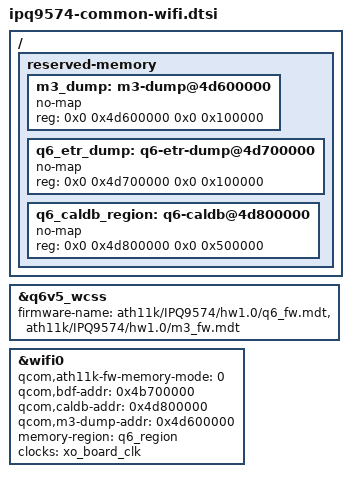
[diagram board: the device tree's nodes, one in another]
// SPDX-License-Identifier: (GPL-2.0+ OR BSD-3-Clause)

/* IPQ9574 AHB radio firmware and dump/calibration memory layout. */
/ {
	reserved-memory {
		m3_dump: m3-dump@4d600000 {
			no-map;
			reg = <0x0 0x4d600000 0x0 0x100000>;
		};

		q6_etr_dump: q6-etr-dump@4d700000 {
			no-map;
			reg = <0x0 0x4d700000 0x0 0x100000>;
		};

		q6_caldb_region: q6-caldb@4d800000 {
			no-map;
			reg = <0x0 0x4d800000 0x0 0x500000>;
		};
	};
};

&q6v5_wcss {
	firmware-name = "ath11k/IPQ9574/hw1.0/q6_fw.mdt",
			"ath11k/IPQ9574/hw1.0/m3_fw.mdt";
};

&wifi0 {
	qcom,ath11k-fw-memory-mode = <0>;
	qcom,bdf-addr = <0x4b700000>;
	qcom,caldb-addr = <0x4d800000>;
	qcom,m3-dump-addr = <0x4d600000>;
	memory-region = <&q6_region>;
	clocks = <&xo_board_clk>;
	clock-names = "xo";
	status = "okay";
};
